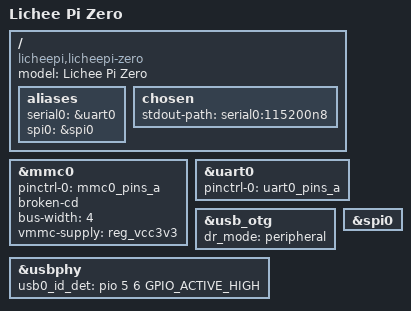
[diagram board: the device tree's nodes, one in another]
/dts-v1/;
#include "sun8i-v3s-uboot.dtsi"
#include "sunxi-common-regulators.dtsi"

/ {
	model = "Lichee Pi Zero";
	compatible = "licheepi,licheepi-zero", "allwinner,sun8i-v3s";

	aliases {
		serial0 = &uart0;
		spi0 = &spi0;
	};

	chosen {
		stdout-path = "serial0:115200n8";
	};
};

&mmc0 {
	pinctrl-0 = <&mmc0_pins_a>;
	pinctrl-names = "default";
	broken-cd;
	bus-width = <4>;
	vmmc-supply = <&reg_vcc3v3>;
	status = "okay";
};

&uart0 {
	pinctrl-0 = <&uart0_pins_a>;
	pinctrl-names = "default";
	status = "okay";
};

&usb_otg {
	dr_mode = "peripheral";
	status = "okay";
};

&usbphy {
	usb0_id_det = <&pio 5 6 GPIO_ACTIVE_HIGH>;
	status = "okay";
};

&spi0 {

		status = "okay";

	//spi-nor@0 {
		//#address-cells = <1>;
		//#size-cells = <1>;
		//compatible = "macronix,mx25u12835f", "jedec,spi-nor";
		//reg = <0>;
		//spi-max-frequency = <50000000>;
		//status = "okay";

		//partitions {
			//compatible = "fixed-partitions";
			//#address-cells = <1>;
			//#size-cells = <1>;

			//partition@0 {
				//label = "u-boot";
				//reg = <0x000000 0x70000>;
				//read-only;
			//};

			//partition@1 {
				//label = "dtb";
				//reg = <0x70000 0x10000>;
				//read-only;
			//};

			//partition@2 {
				//label = "kernel";
				//reg = <0x80000 0x580000>;
				//read-only;
			//};

			//partition@3 {
				//label = "rom";
				//reg = <0x600000 0x700000>;
				//read-only;
			//};

			//partition@4 {
				//label = "overlay";
				//reg = <0xd00000 0x300000>;
			//};
		//};
	//};


};
